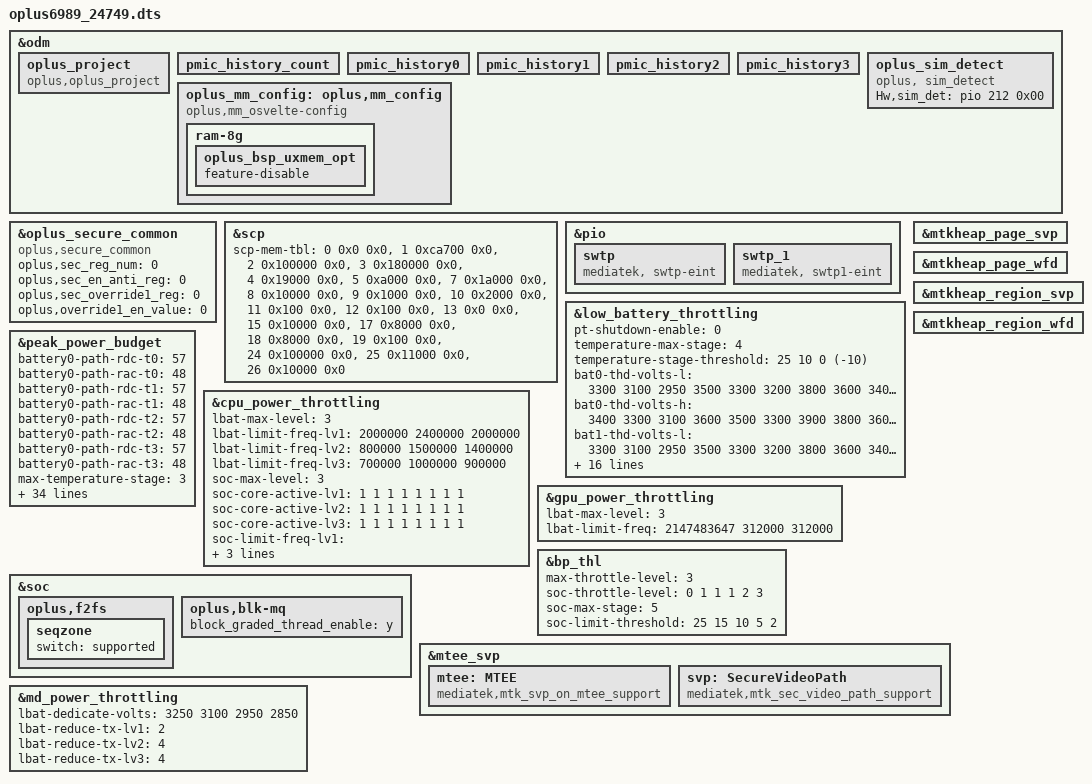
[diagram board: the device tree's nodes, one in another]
// SPDX-License-Identifier: (GPL-2.0 OR MIT)
/*
 * Copyright (C) 2022 MediaTek Inc.
 */
#include "k6989v2_64.dts"

/* Add for CaymanB(24749) fingerprint device-tree */
/* #ifdef CONFIG_UFF_FINGERPRINT */
#include "mediatek/oplus_uff_24610.dtsi"
/* #endif CONFIG_UFF_FINGERPRINT */

//#ifdef OPLUS_FEATURE_SENSOR
#include "mediatek/oplus_sensor_24749.dtsi"
//#endif
//#ifdef OPLUS_FEATURE_CHG_BASIC

//endif

&odm {
    /*OPLUS_FEATURE_OEM_OCDT oppo project start */
	oplus_project:oplus_project {
		compatible = "oplus,oplus_project";
	};

	pmic_history_count:pmic_history_count {
 	};
 	pmic_history0:pmic_history0 {
 	};
 	pmic_history1:pmic_history1 {
 	};
 	pmic_history2:pmic_history2 {
 	};
 	pmic_history3:pmic_history3 {
 	};
};

&odm {
	oplus_mm_config: oplus,mm_config {
		compatible = "oplus,mm_osvelte-config";
		ram-8g {
			oplus_bsp_uxmem_opt {
				feature-disable;
			};
		};
	};
};

&oplus_secure_common {
    compatible = "oplus,secure_common";
    oplus,sec_reg_num = <0>;
    oplus,sec_en_anti_reg = <0>;
    oplus,sec_override1_reg = <0>;
    oplus,override1_en_value = <0>;
};

&scp {
	// feature ID, size, alignment
	scp-mem-tbl = <0 0x0 0x0>, // secure dump, its size is in secure-dump-size
                  <1 0xca700 0x0>, // vow
                  <2 0x100000 0x0>, // sensor mai
                  <3 0x180000 0x0>, // logger
                  <4 0x19000 0x0>, // audio
                  <5 0xa000 0x0>, // vow bargein
                  <7 0x1a000 0x0>, // ultrasound
                  <8 0x10000 0x0>, // sensor supper
                  <9 0x1000 0x0>, // sensor list
                  <10 0x2000 0x0>, // sensor debug
                  <11 0x100 0x0>, // sensor custom writer
                  <12 0x100 0x0>, // sensor custom reader
                  <13 0x0 0x0>, /* aov */
                  <15 0x10000 0x0>, // aod
                  <17 0x8000 0x0>, // scp chre from
                  <18 0x8000 0x0>, // scp chre to
                  <19 0x100 0x0>,  // low power debug
                  // #ifdef OPLUS_FEATURE_SENSOR_SMEM
                  <24 0x100000  0x0>, // sensor share memor
                  <25 0x11000 0x0>, // sensor monitor
                  <26 0x10000 0x0>; // pseudo sensor for data/fault inject
                  // #endif OPLUS_FEATURE_SENSOR_SMEM
};

&pio {
	//#ifdef OPLUS_VENDOR_SWTP
	swtp: swtp {
		compatible = "mediatek, swtp-eint";
	};
	 swtp_1: swtp_1 {
        compatible = "mediatek, swtp1-eint";
    };
	//#endif  /*OPLUS_VENDOR_SWTP*/
};

&low_battery_throttling {
	pt-shutdown-enable = <0>;
	temperature-max-stage = <4>;
	temperature-stage-threshold = <25 10 0 (-10)>;
	bat0-thd-volts-l = <
			3300 3100 2950
			3500 3300 3200
			3800 3600 3400
			4000 3800 3500
			4200 3940 3580>;
	bat0-thd-volts-h = <
			3400 3300 3100
			3600 3500 3300
			3900 3800 3600
			4100 4000 3800
			4300 4200 3940>;
	bat1-thd-volts-l = <
			3300 3100 2950
			3500 3300 3200
			3800 3600 3400
			4000 3800 3500
			4200 3940 3580>;
	bat1-thd-volts-h = <
			3400 3300 3100
			3600 3500 3300
			3900 3800 3600
			4100 4000 3800
			4300 4200 3940>;

	bat0-aging-threshold = <1000 2000>;
	bat0-aging-volts-t0 =  <0 0>;
	bat0-aging-volts-t1 =  <0 0>;
	bat0-aging-volts-t2 =  <0 0>;
	bat0-aging-volts-t3 =  <0 0>;
	bat0-aging-volts-t4 =  <0 0>;
	bat1-aging-threshold = <1000 2000>;
	bat1-aging-volts-t0 =  <0 0>;
	bat1-aging-volts-t1 =  <0 0>;
	bat1-aging-volts-t2 =  <0 0>;
	bat1-aging-volts-t3 =  <0 0>;
	bat1-aging-volts-t4 =  <0 0>;
	throttle-level = <0 1 2 3>,
			 <0 1 2 3>,
			 <0 1 2 3>,
			 <0 1 2 3>,
			 <0 1 2 3>;
};

&peak_power_budget {
	battery0-path-rdc-t0 = <57>;
	battery0-path-rac-t0 = <48>;
	battery0-path-rdc-t1 = <57>;
	battery0-path-rac-t1 = <48>;
	battery0-path-rdc-t2 = <57>;
	battery0-path-rac-t2 = <48>;
	battery0-path-rdc-t3 = <57>;
	battery0-path-rac-t3 = <48>;
	max-temperature-stage = <3>;
	temperature-threshold = <25 10 0>;
	system-ocp = <13000>;
	system-uvlo = <2600>;

	bat-ocv-table-num = <6>;

	bat0-ocv-table-t0-temperature = <50>;
	bat0-ocv-table-t0-qmax = <6796>;
	bat0-ocv-table-t0-size = <100>;
	bat0-ocv-table-t0 = <
	0      44580  0  200
	704    44453  0  200
	1406   44341  0  200
	2110   44242  0  200
	2812   44146  0  200
	3516   44053  0  200
	4218   43961  0  200
	4922   43863  0  200
	5624   43768  0  200
	6328   43670  0  200
	7030   43567  0  200
	7734   43463  0  200
	8436   43355  0  200
	9140   43243  0  200
	9842   43132  0  200
	10546  43019  0  200
	11248  42901  0  200
	11952  42778  0  200
	12654  42661  0  200
	13358  42539  0  200
	14060  42417  0  200
	14764  42294  0  200
	15466  42171  0  200
	16170  42049  0  200
	16872  41926  0  200
	17576  41800  0  200
	18278  41673  0  200
	18982  41538  0  200
	19684  41391  0  200
	20388  41211  0  200
	21090  41016  0  200
	21794  40844  0  200
	22496  40707  0  200
	23200  40587  0  200
	23904  40473  0  200
	24606  40363  0  200
	25310  40254  0  200
	26012  40150  0  200
	26716  40050  0  200
	27418  39952  0  200
	28122  39855  0  200
	28824  39763  0  200
	29528  39667  0  200
	30230  39579  0  200
	30934  39492  0  200
	31636  39403  0  200
	32340  39307  0  200
	33042  39189  0  200
	33746  39044  0  200
	34448  38902  0  200
	35152  38779  0  200
	35854  38664  0  200
	36558  38551  0  200
	37260  38445  0  200
	37964  38343  0  200
	38666  38236  0  200
	39370  38116  0  200
	40072  37990  0  200
	40776  37879  0  200
	41478  37761  0  200
	42182  37646  0  200
	42884  37551  0  200
	43588  37476  0  200
	44290  37410  0  200
	44994  37343  0  200
	45696  37264  0  200
	46400  37155  0  200
	47104  37049  0  200
	47806  36938  0  200
	48510  36820  0  200
	49212  36697  0  200
	49916  36570  0  200
	50618  36437  0  200
	51322  36295  0  200
	52024  36143  0  200
	52728  35984  0  200
	53430  35821  0  200
	54134  35658  0  200
	54836  35496  0  200
	55540  35339  0  200
	56242  35186  0  200
	56946  35031  0  200
	57648  34878  0  200
	58352  34714  0  200
	59054  34541  0  200
	59758  34360  0  200
	60460  34163  0  200
	61164  33947  0  200
	61866  33716  0  200
	62570  33473  0  200
	63272  33220  0  517
	63976  32973  0  516
	64678  32730  0  527
	65382  32492  0  552
	66084  32245  0  596
	66788  31969  0  669
	67490  31627  0  774
	68194  31162  0  900
	68896  30626  0  1081
	69600  30626  0  1641  >;

	bat0-ocv-table-t1-temperature = <25>;
	bat0-ocv-table-t1-qmax = <6848>;
	bat0-ocv-table-t1-size = <100>;
	bat0-ocv-table-t1 = <
	0      44544  0  200
	694    44414  0  200
	1390   44306  0  200
	2084   44206  0  200
	2780   44112  0  200
	3474   44018  0  200
	4170   43922  0  200
	4864   43827  0  200
	5560   43728  0  200
	6254   43628  0  200
	6950   43524  0  200
	7644   43419  0  200
	8340   43310  0  200
	9034   43197  0  200
	9730   43084  0  200
	10424  42968  0  200
	11120  42852  0  200
	11814  42732  0  200
	12510  42608  0  200
	13204  42486  0  200
	13898  42363  0  200
	14594  42240  0  200
	15288  42116  0  200
	15984  41992  0  200
	16678  41871  0  200
	17374  41745  0  200
	18068  41622  0  200
	18764  41495  0  200
	19458  41357  0  200
	20154  41200  0  200
	20848  41007  0  200
	21544  40803  0  200
	22238  40643  0  200
	22934  40509  0  200
	23628  40389  0  200
	24324  40276  0  200
	25018  40169  0  200
	25714  40069  0  200
	26408  39967  0  200
	27104  39870  0  200
	27798  39775  0  200
	28492  39685  0  200
	29188  39596  0  200
	29882  39508  0  200
	30578  39423  0  200
	31272  39342  0  200
	31968  39259  0  200
	32662  39178  0  200
	33358  39086  0  200
	34052  38983  0  200
	34748  38873  0  200
	35442  38758  0  200
	36138  38643  0  200
	36832  38531  0  200
	37528  38428  0  200
	38222  38328  0  200
	38918  38217  0  200
	39612  38096  0  200
	40308  37977  0  200
	41002  37862  0  200
	41696  37743  0  200
	42392  37619  0  200
	43086  37533  0  200
	43782  37462  0  200
	44476  37400  0  200
	45172  37335  0  200
	45866  37247  0  200
	46562  37127  0  200
	47256  37004  0  200
	47952  36885  0  200
	48646  36762  0  200
	49342  36636  0  200
	50036  36504  0  200
	50732  36366  0  200
	51426  36219  0  200
	52122  36064  0  200
	52816  35902  0  200
	53512  35738  0  200
	54206  35572  0  200
	54902  35411  0  200
	55596  35250  0  200
	56290  35090  0  200
	56986  34930  0  200
	57680  34767  0  200
	58376  34595  0  200
	59070  34410  0  200
	59766  34208  0  200
	60460  33993  0  200
	61156  33760  0  200
	61850  33508  0  200
	62546  33246  0  1721
	63240  32991  0  1801
	63936  32748  0  1908
	64630  32506  0  2029
	65326  32259  0  2170
	66020  31986  0  2336
	66716  31640  0  2530
	67410  31159  0  2723
	68106  30477  0  2867
	68800  29548  0  2984 >;

	bat0-ocv-table-t2-temperature = <10>;
	bat0-ocv-table-t2-qmax = <6400>;
	bat0-ocv-table-t2-size = <100>;
	bat0-ocv-table-t2 = <
	0      44525  0  200
	704    44372  0  200
	1406   44257  0  200
	2110   44160  0  200
	2812   44070  0  200
	3516   43981  0  200
	4218   43890  0  200
	4922   43802  0  200
	5624   43709  0  200
	6328   43611  0  200
	7030   43508  0  200
	7734   43404  0  200
	8436   43301  0  200
	9140   43194  0  200
	9842   43084  0  200
	10546  42969  0  200
	11248  42855  0  200
	11952  42734  0  200
	12654  42610  0  200
	13358  42489  0  200
	14060  42365  0  200
	14764  42240  0  200
	15466  42115  0  200
	16170  41990  0  200
	16872  41863  0  200
	17576  41733  0  200
	18278  41602  0  200
	18982  41466  0  200
	19684  41316  0  200
	20388  41140  0  200
	21090  40949  0  200
	21794  40766  0  200
	22496  40605  0  200
	23200  40457  0  200
	23904  40331  0  200
	24606  40220  0  200
	25310  40111  0  200
	26012  40006  0  200
	26716  39903  0  200
	27418  39800  0  200
	28122  39703  0  200
	28824  39611  0  200
	29528  39518  0  200
	30230  39425  0  200
	30934  39337  0  200
	31636  39253  0  200
	32340  39169  0  200
	33042  39082  0  200
	33746  38995  0  200
	34448  38912  0  200
	35152  38815  0  200
	35854  38707  0  200
	36558  38589  0  200
	37260  38469  0  200
	37964  38360  0  200
	38666  38256  0  200
	39370  38139  0  200
	40072  38013  0  200
	40776  37883  0  200
	41478  37762  0  200
	42182  37638  0  200
	42884  37520  0  200
	43588  37426  0  200
	44290  37357  0  200
	44994  37294  0  200
	45696  37220  0  200
	46400  37127  0  200
	47104  36980  0  200
	47806  36847  0  200
	48510  36721  0  200
	49212  36595  0  200
	49916  36467  0  200
	50618  36335  0  200
	51322  36197  0  200
	52024  36050  0  200
	52728  35891  0  200
	53430  35724  0  200
	54134  35555  0  200
	54836  35386  0  200
	55540  35217  0  200
	56242  35050  0  200
	56946  34886  0  200
	57648  34722  0  200
	58352  34548  0  200
	59054  34368  0  200
	59758  34176  0  200
	60460  33962  0  200
	61164  33730  0  200
	61866  33484  0  200
	62570  33225  0  200
	63272  32959  0  1601
	63976  32703  0  1679
	64678  32457  0  1757
	65382  32208  0  1856
	66084  31946  0  1967
	66788  31826  0  2199
	67490  31826  0  2391
	68194  31826  0  2391
	68896  31826  0  2391
	69600  31826  0  2391 >;

	bat0-ocv-table-t3-temperature = <0>;
	bat0-ocv-table-t3-qmax = <6008>;
	bat0-ocv-table-t3-size = <100>;
	bat0-ocv-table-t3 = <
	0      44580  0  200
	704    44417  0  200
	1406   44300  0  200
	2110   44199  0  200
	2812   44104  0  200
	3516   44014  0  200
	4218   43925  0  200
	4922   43833  0  200
	5624   43740  0  200
	6328   43648  0  200
	7030   43550  0  200
	7734   43452  0  200
	8436   43351  0  200
	9140   43244  0  200
	9842   43135  0  200
	10546  43026  0  200
	11248  42917  0  200
	11952  42796  0  200
	12654  42677  0  200
	13358  42557  0  200
	14060  42434  0  200
	14764  42305  0  200
	15466  42177  0  200
	16170  42049  0  200
	16872  41912  0  200
	17576  41770  0  200
	18278  41613  0  200
	18982  41451  0  200
	19684  41279  0  200
	20388  41105  0  200
	21090  40938  0  200
	21794  40784  0  200
	22496  40644  0  200
	23200  40513  0  200
	23904  40393  0  200
	24606  40278  0  200
	25310  40167  0  200
	26012  40061  0  200
	26716  39958  0  200
	27418  39855  0  200
	28122  39752  0  200
	28824  39654  0  200
	29528  39562  0  200
	30230  39468  0  200
	30934  39376  0  200
	31636  39284  0  200
	32340  39197  0  200
	33042  39111  0  200
	33746  39017  0  200
	34448  38920  0  200
	35152  38826  0  200
	35854  38719  0  200
	36558  38605  0  200
	37260  38491  0  200
	37964  38374  0  200
	38666  38250  0  200
	39370  38118  0  200
	40072  37983  0  200
	40776  37857  0  200
	41478  37727  0  200
	42182  37609  0  200
	42884  37514  0  200
	43588  37436  0  200
	44290  37365  0  200
	44994  37289  0  200
	45696  37192  0  200
	46400  37034  0  200
	47104  36871  0  200
	47806  36736  0  200
	48510  36613  0  200
	49212  36490  0  200
	49916  36362  0  200
	50618  36228  0  200
	51322  36085  0  200
	52024  35932  0  200
	52728  35773  0  200
	53430  35606  0  200
	54134  35433  0  200
	54836  35255  0  200
	55540  35072  0  200
	56242  34891  0  1652
	56946  34716  0  1759
	57648  34535  0  1868
	58352  34344  0  1984
	59054  34149  0  2125
	59758  33935  0  2312
	60460  33706  0  2489
	61164  33466  0  2647
	61866  33217  0  2791
	62570  33023  0  2963
	63272  33023  0  3140
	63976  33023  0  3140
	64678  33023  0  3140
	65382  33023  0  3140
	66084  33023  0  3140
	66788  33023  0  3140
	67490  33023  0  3140
	68194  33023  0  3140
	68896  33023  0  3140
	69600  33023  0  3140 >;

	bat0-ocv-table-t4-temperature = <(-10)>;
	bat0-ocv-table-t4-qmax = <5554>;
	bat0-ocv-table-t4-size = <100>;
	bat0-ocv-table-t4 = <
	0      44587  0  200
	704    44396  0  200
	1406   44247  0  200
	2110   44121  0  200
	2812   44008  0  200
	3516   43897  0  200
	4218   43786  0  200
	4922   43681  0  200
	5624   43572  0  200
	6328   43463  0  200
	7030   43359  0  200
	7734   43247  0  200
	8436   43133  0  200
	9140   43018  0  200
	9842   42904  0  200
	10546  42787  0  200
	11248  42663  0  200
	11952  42542  0  200
	12654  42418  0  200
	13358  42292  0  200
	14060  42167  0  200
	14764  42039  0  200
	15466  41906  0  200
	16170  41767  0  200
	16872  41619  0  200
	17576  41467  0  200
	18278  41314  0  200
	18982  41157  0  200
	19684  41003  0  200
	20388  40848  0  200
	21090  40694  0  200
	21794  40549  0  200
	22496  40415  0  200
	23200  40290  0  200
	23904  40170  0  200
	24606  40055  0  200
	25310  39944  0  200
	26012  39835  0  200
	26716  39734  0  200
	27418  39638  0  200
	28122  39536  0  200
	28824  39443  0  200
	29528  39351  0  200
	30230  39263  0  200
	30934  39176  0  200
	31636  39085  0  200
	32340  38995  0  200
	33042  38910  0  200
	33746  38827  0  200
	34448  38740  0  200
	35152  38646  0  200
	35854  38554  0  200
	36558  38457  0  200
	37260  38352  0  200
	37964  38243  0  200
	38666  38130  0  200
	39370  38009  0  200
	40072  37883  0  200
	40776  37758  0  200
	41478  37633  0  200
	42182  37507  0  1719
	42884  37408  0  1726
	43588  37330  0  1744
	44290  37262  0  1764
	44994  37193  0  1784
	45696  37109  0  1806
	46400  36979  0  1833
	47104  36761  0  1871
	47806  36580  0  1937
	48510  36437  0  1984
	49212  36303  0  2039
	49916  36167  0  2097
	50618  36024  0  2150
	51322  35864  0  2226
	52024  35689  0  2321
	52728  35510  0  2416
	53430  35315  0  2527
	54134  35118  0  2642
	54836  34916  0  2783
	55540  34709  0  2948
	56242  34500  0  3134
	56946  34286  0  3352
	57648  34083  0  3594
	58352  34083  0  3802
	59054  34083  0  3802
	59758  34083  0  3802
	60460  34083  0  3802
	61164  34083  0  3802
	61866  34083  0  3802
	62570  34083  0  3802
	63272  34083  0  3802
	63976  34083  0  3802
	64678  34083  0  3802
	65382  34083  0  3802
	66084  34083  0  3802
	66788  34083  0  3802
	67490  34083  0  3802
	68194  34083  0  3802
	68896  34083  0  3802
	69600  34083  0  3802 >;

	bat0-ocv-table-t5-temperature = <(-20)>;
	bat0-ocv-table-t5-qmax = <4906>;
	bat0-ocv-table-t5-size = <100>;
	bat0-ocv-table-t5 = <
	0      44680  0  4100
	704    44391  0  4100
	1406   44178  0  4115
	2110   43999  0  4110
	2812   43837  0  4082
	3516   43681  0  4044
	4218   43530  0  4005
	4922   43384  0  3975
	5624   43242  0  3948
	6328   43106  0  3935
	7030   42970  0  3912
	7734   42838  0  3881
	8436   42707  0  3855
	9140   42584  0  3844
	9842   42458  0  3833
	10546  42315  0  3812
	11248  42184  0  3823
	11952  42047  0  3799
	12654  41922  0  3770
	13358  41788  0  3747
	14060  41655  0  3729
	14764  41522  0  3708
	15466  41387  0  3684
	16170  41254  0  3661
	16872  41113  0  3638
	17576  40977  0  3624
	18278  40840  0  3607
	18982  40709  0  3596
	19684  40574  0  3585
	20388  40441  0  3570
	21090  40315  0  3551
	21794  40193  0  3534
	22496  40069  0  3519
	23200  39955  0  3519
	23904  39841  0  3509
	24606  39731  0  3499
	25310  39626  0  3501
	26012  39528  0  3493
	26716  39433  0  3484
	27418  39335  0  3482
	28122  39240  0  3478
	28824  39158  0  3487
	29528  39066  0  3467
	30230  38978  0  3459
	30934  38895  0  3460
	31636  38809  0  3471
	32340  38722  0  3477
	33042  38637  0  3478
	33746  38555  0  3494
	34448  38473  0  3502
	35152  38392  0  3434
	35854  38310  0  3484
	36558  38228  0  3485
	37260  38140  0  3451
	37964  38050  0  3448
	38666  37961  0  3465
	39370  37866  0  3460
	40072  37769  0  3471
	40776  37670  0  3491
	41478  37583  0  3508
	42182  37491  0  3517
	42884  37406  0  3540
	43588  37330  0  3567
	44290  37260  0  3599
	44994  37188  0  3639
	45696  37112  0  3669
	46400  37003  0  3724
	47104  36834  0  3775
	47806  36623  0  3832
	48510  36417  0  3873
	49212  36231  0  3941
	49916  36059  0  4028
	50618  35891  0  4123
	51322  35721  0  4244
	52024  35547  0  4361
	52728  35361  0  4483
	53430  35342  0  4569
	54134  35342  0  4589
	54836  35342  0  4589
	55540  35342  0  4589
	56242  35342  0  4589
	56946  35342  0  4589
	57648  35342  0  4589
	58352  35342  0  4589
	59054  35342  0  4589
	59758  35342  0  4589
	60460  35342  0  4589
	61164  35342  0  4589
	61866  35342  0  4589
	62570  35342  0  4589
	63272  35342  0  4589
	63976  35342  0  4589
	64678  35342  0  4589
	65382  35342  0  4589
	66084  35342  0  4589
	66788  35342  0  4589
	67490  35342  0  4589
	68194  35342  0  4589
	68896  35342  0  4589
	69600  35342  0  4589 >;
};

&cpu_power_throttling {
	lbat-max-level = <3>;
	lbat-limit-freq-lv1 = < 2000000 2400000 2000000>;
	lbat-limit-freq-lv2 = < 800000 1500000 1400000>;
	lbat-limit-freq-lv3 = < 700000 1000000 900000>;

	soc-max-level = <3>;
	soc-core-active-lv1 = < 1 1 1 1 1 1 1 1 >;
	soc-core-active-lv2 = < 1 1 1 1 1 1 1 1 >;
	soc-core-active-lv3 = < 1 1 1 1 1 1 1 1 >;

	soc-limit-freq-lv1 = < 2147483647  2147483647 2147483647 >;
	soc-limit-freq-lv2 = < 900000 2000000 1800000>;
	soc-limit-freq-lv3 = < 900000 1500000 1500000>;
};

&gpu_power_throttling {
	lbat-max-level = <3>;
	lbat-limit-freq = <2147483647 312000 312000>;
};
&bp_thl {
	max-throttle-level = <3>;   //+lv3
	soc-throttle-level = <0 1 1 1 2 3>;
	soc-max-stage = <5>;
	soc-limit-threshold = <25 15 10 5 2>;
};

&soc {
	oplus,f2fs {
		seqzone {
			switch = "supported";
		};
	};

	//Kernel.Storage, 2024/10/9, add for blk-mq.c block_graded_thread_enable
	oplus,blk-mq {
		block_graded_thread_enable = "y";
	};
};
/*#ifdef OPLUS_FEATURE_SECURITY_COMMON*/

&mtkheap_page_svp {
    status = "ok";
};
&mtkheap_page_wfd {
    status = "ok";
};
&mtkheap_region_svp {
    status = "ok";
};
&mtkheap_region_wfd {
    status = "ok";
};
&mtee_svp {
	mtee: MTEE {
		compatible = "mediatek,mtk_svp_on_mtee_support";
	};
	svp: SecureVideoPath {
		compatible = "mediatek,mtk_sec_video_path_support";
	};
};
/*#endif OPLUS_FEATURE_SECURITY_COMMON*/

&odm {
/* Add for sim detect */
    oplus_sim_detect {
        compatible = "oplus, sim_detect";
        Hw,sim_det = <&pio 212 0x00>;
    };
};

&md_power_throttling{
		lbat-dedicate-volts = <3250 3100 2950 2850>;

		lbat-reduce-tx-lv1 = <2>;
		lbat-reduce-tx-lv2 = <4>;
		lbat-reduce-tx-lv3 = <4>;
};

#include <oplus6989_24749/cust.dtsi>
#include "mediatek/nfc/mt6989_24610_sn220.dtsi"

#include "mediatek/cust_mt6989_caymanbn_24749_camera_v4l2.dtsi"
#include "mediatek/cust_mt6989_24749_audio.dtsi"

#include "mediatek/oplus_misc_24749.dtsi"
#include "mediatek/oplus_tp_24749.dtsi"
#include "mediatek/oplus_charge_24749.dtsi"
#include "oplus_connectivity_24749.dtsi"
#include "mediatek/display/oplus6989_24749_display.dtsi"
/*End of this file, DO NOT ADD ANYTHING HERE*/
